# GD32E50x_CL register map
File version: 1.0
CPU: CM33 r0p0, little endian, MPU, FPU, 4 interrupt priority bits
Registers are 32-bit, read-write, reset 0x0 unless marked. A register's access mark holds for its fields unless they carry their own. Offsets are from the block's base; [hi:lo] are bit positions.

## DAC — Digital-to-analog converter
Base 0x40007400
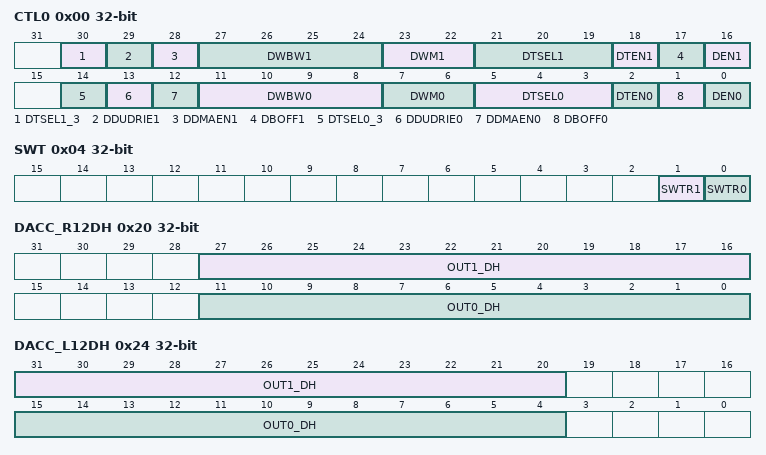
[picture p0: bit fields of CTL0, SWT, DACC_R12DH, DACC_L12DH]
0x00 CTL0 — control register 0
  [30] DTSEL1_3 — DAC_OUT1 trigger selection bit[3], refer to DTSEL1[2:0]
  [29] DDUDRIE1 — DAC_OUT1 DMA underrun interrupt enable
  [28] DDMAEN1 — DAC1 DMA enable
  [27:24] DWBW1 — DAC1 noise wave bit width
  [23:22] DWM1 — DAC1 noise wave mode
  [21:19] DTSEL1 — DAC1 trigger selection
  [18] DTEN1 — DAC1 trigger enable
  [17] DBOFF1 — DAC1 output buffer turn off
  [16] DEN1 — DAC1 enable
  [14] DTSEL0_3 — DAC_OUT0 trigger selection bit[3], refer to DTSEL0[2:0]
  [13] DDUDRIE0 — DAC_OUT0 DMA underrun interrupt enable
  [12] DDMAEN0 — DAC0 DMA enable
  [11:8] DWBW0 — DAC0 noise wave bit width
  [7:6] DWM0 — DAC0 noise wave mode
  [5:3] DTSEL0 — DAC0 trigger selection
  [2] DTEN0 — DAC0 trigger enable
  [1] DBOFF0 — DAC0 output buffer turn off
  [0] DEN0 — DAC0 enable
0x04 SWT wo — software trigger register
  [1] SWTR1 — DAC1 software trigger
  [0] SWTR0 — DAC0 software trigger
0x08 OUT0_R12DH — DAC_OUT0 12-bit right-aligned data holding register
  [11:0] OUT0_DH — DAC_OUT0 12-bit right-aligned data
0x0C OUT0_L12DH — DAC_OUT0 12-bit left-aligned data holding register
  [15:4] OUT0_DH — DAC_OUT0 12-bit left-aligned data
0x10 OUT0_R8DH — DAC_OUT0 8-bit right aligned data holding register
  [7:0] OUT0_DH — DAC_OUT0 8-bit right-aligned data
0x14 OUT1_R12DH — DAC_OUT1 12-bit right-aligned data holding register
  [11:0] OUT1_DH — DAC_OUT1 12-bit right-aligned data
0x18 OUT1_L12DH — DAC_OUT1 12-bit left aligned data holding register
  [15:4] OUT1_DH — DAC_OUT1 12-bit left-aligned data
0x1C OUT1_R8DH — DAC_OUT1 8-bit right aligned data holding register
  [7:0] OUT1_DH — DAC_OUT1 8-bit right-aligned data
0x20 DACC_R12DH — DAC concurrent mode 12-bit right-aligned data holding register
  [27:16] OUT1_DH — DAC_OUT1 12-bit right-aligned data
  [11:0] OUT0_DH — DAC_OUT0 12-bit right-aligned data
0x24 DACC_L12DH — DAC concurrent mode 12-bit left aligned data holding register
  [31:20] OUT1_DH — DAC_OUT1 12-bit left-aligned data
  [15:4] OUT0_DH — DAC_OUT0 12-bit left-aligned data
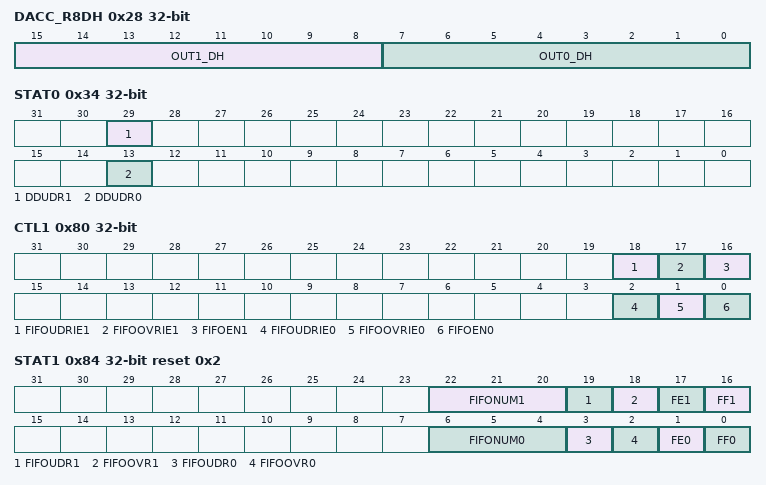
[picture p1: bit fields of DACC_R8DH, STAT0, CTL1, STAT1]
0x28 DACC_R8DH — DAC concurrent mode 8-bit right aligned data holding register
  [15:8] OUT1_DH — DAC_OUT1 8-bit right-aligned data
  [7:0] OUT0_DH — DAC_OUT0 8-bit right-aligned data
0x2C OUT0_DO ro — DAC_OUT0 data output register
  [11:0] OUT0_DO — DAC_OUT0 data output
0x30 OUT1_DO ro — DAC_OUT1 data output register
  [11:0] OUT1_DO — DAC_OUT1 data output
0x34 STAT0 — DAC Status register 0
  [29] DDUDR1 — DAC_OUT1 DMA underrun flag
  [13] DDUDR0 — DAC_OUT0 DMA underrun flag
0x80 CTL1 — DAC Control Register 1
  [18] FIFOUDRIE1 — DAC_OUT1 FIFO underflow interrupt enable
  [17] FIFOOVRIE1 — DAC_OUT1 FIFO overflow interrupt enable
  [16] FIFOEN1 — DAC_OUT1 data FIFO enable
  [2] FIFOUDRIE0 — DAC_OUT0 FIFO underflow interrupt enable
  [1] FIFOOVRIE0 — DAC_OUT0 FIFO overflow interrupt enable
  [0] FIFOEN0 — DAC_OUT0 data FIFO enable
0x84 STAT1 access per field reset 0x2 — DAC Status register 1
  [22:20] FIFONUM1 ro — Number of data in the DAC_OUT1 FIFO
  [19] FIFOUDR1 rw — DAC_OUT1 FIFO underflow flag
  [18] FIFOOVR1 rw — DAC_OUT1 FIFO overflow flag
  [17] FE1 ro — DAC_OUT1 FIFO empty flag
  [16] FF1 ro — DAC_OUT1 FIFO full flag
  [6:4] FIFONUM0 ro — Number of data in the DAC_OUT0 FIFO
  [3] FIFOUDR0 rw — DAC_OUT0 FIFO underflow flag
  [2] FIFOOVR0 rw — DAC_OUT0 FIFO overflow flag
  [1] FE0 ro — DAC_OUT0 FIFO empty flag
  [0] FF0 ro — DAC_OUT0 FIFO full flag

## DBG — Debug support
Base 0xE0044000
0x00 ID ro — ID code register
  [31:0] ID_CODE — DBG ID code register
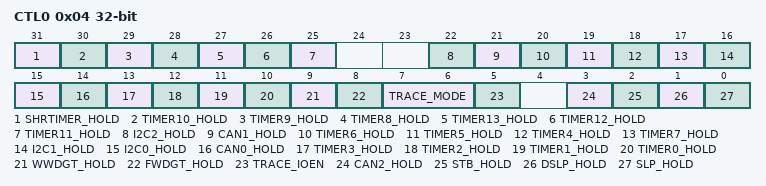
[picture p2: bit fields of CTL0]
0x04 CTL0 — Control register 0
  [31] SHRTIMER_HOLD — SHRTIMER hold bit
  [30] TIMER10_HOLD — TIMER 10 hold bit
  [29] TIMER9_HOLD — TIMER 9 hold bit
  [28] TIMER8_HOLD — TIMER 8 hold bit
  [27] TIMER13_HOLD — TIMER 13 hold bit
  [26] TIMER12_HOLD — TIMER 12 hold bit
  [25] TIMER11_HOLD — TIMER 11 hold bit
  [22] I2C2_HOLD — I2C2 hold bit
  [21] CAN1_HOLD — CAN1 hold bit
  [20] TIMER6_HOLD — TIMER 6 hold bit
  [19] TIMER5_HOLD — TIMER 5 hold bit
  [18] TIMER4_HOLD
  [17] TIMER7_HOLD
  [16] I2C1_HOLD — I2C1 hold bit
  [15] I2C0_HOLD — I2C0 hold bit
  [14] CAN0_HOLD — CAN0 hold bit
  [13] TIMER3_HOLD — TIMER 23 hold bit
  [12] TIMER2_HOLD — TIMER 2 hold bit
  [11] TIMER1_HOLD — TIMER 1 hold bit
  [10] TIMER0_HOLD — TIMER 0 hold bit
  [9] WWDGT_HOLD — WWDGT hold bit
  [8] FWDGT_HOLD — FWDGT hold bit
  [7:6] TRACE_MODE — Trace pin allocation mode
  [5] TRACE_IOEN — Trace pin allocation enable
  [3] CAN2_HOLD — CAN2 hold bit
  [2] STB_HOLD — Standby mode hold register
  [1] DSLP_HOLD — Deep-sleep mode hold register
  [0] SLP_HOLD — Sleep mode hold register
